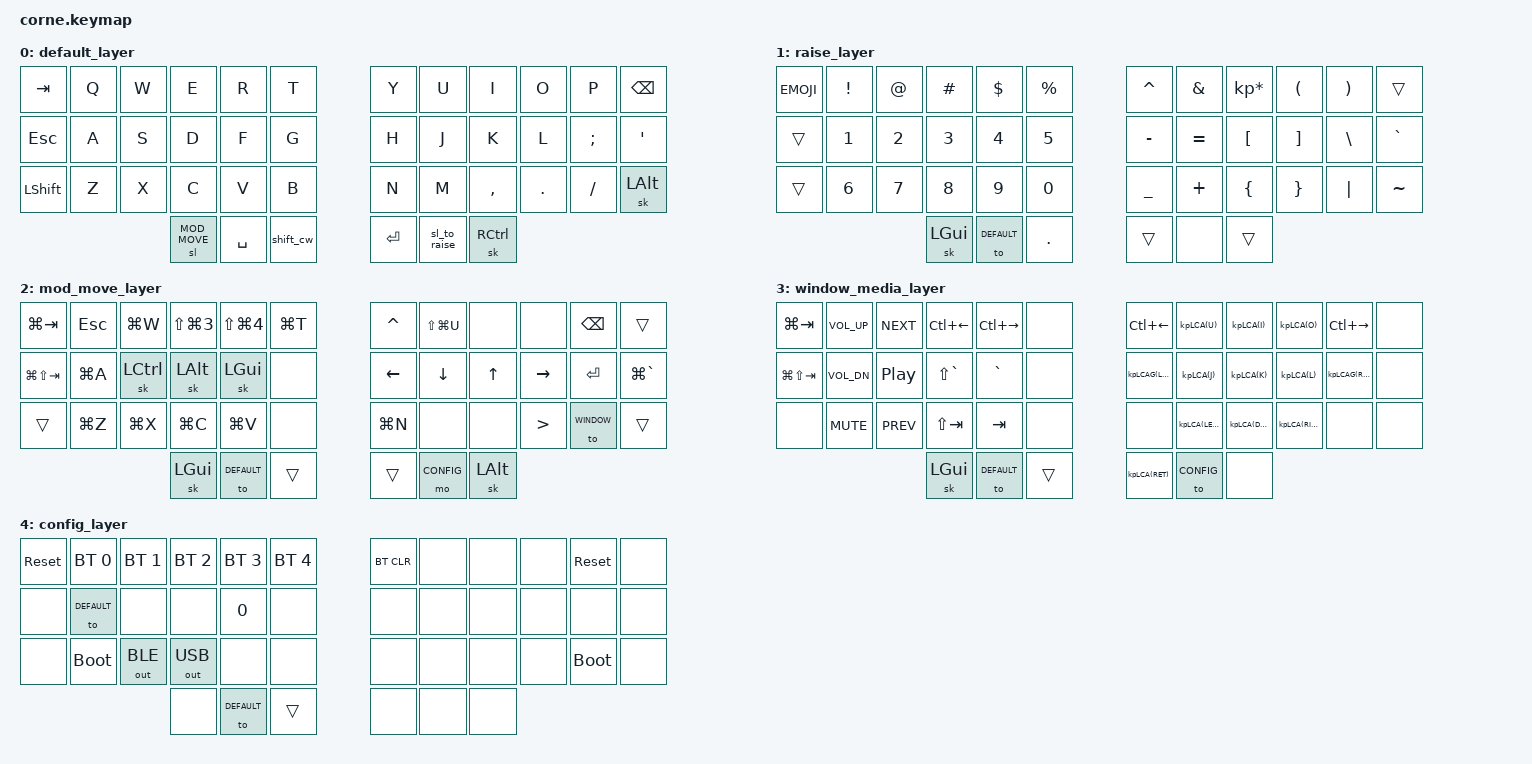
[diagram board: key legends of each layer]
/*
 * Copyright (c) 2020 The ZMK Contributors
 *
 * SPDX-License-Identifier: MIT
 */

#include <behaviors.dtsi>
#include <dt-bindings/zmk/keys.h>
#include <dt-bindings/zmk/bt.h>
#include <dt-bindings/zmk/outputs.h>


#define DEFAULT   0
#define RAISE     1
#define MOD_MOVE  2
#define WINDOW    3
#define CONFIG    4

#define kpLCA(keycode) &kp LC(LA(keycode))
#define kpLCAG(keycode) &kp LC(LA(LG(keycode)))
#define EMOJI LG(LC(SPACE))

&mt {
    tapping-term-ms = <400>;
};

&sk {
    release-after-ms = <10000>;
};

&sl {
    release-after-ms = <10000>;
};

/ {
        behaviors {
           shift_cw: shift_capsword {
                    compatible = "zmk,behavior-tap-dance";
                    label = "STICKY_SHIFT_DOUBLE_TAP_CAPWORD";
                    #binding-cells = <0>;
                    tapping-term-ms = <200>;
                    bindings = <&sk LSHIFT>, <&caps_word>;
           };
           sl_to_raise: sticky_layer_to_layer_raise {
                    compatible = "zmk,behavior-tap-dance";
                    label = "STICKY_LAYER_DOUBLE_TAP_TO_LAYER_RAISE";
                    #binding-cells = <0>;
                    tapping-term-ms = <400>;
                    bindings = <&sl RAISE>, <&to RAISE>;
           };
           my_gresc: grave_escape {
                    compatible = "zmk,behavior-mod-morph";
                    label = "GRAVE_ESCAPE";
                    #binding-cells = <0>;
                    bindings = <&kp ESC>, <&kp GRAVE>;
                    mods = <(MOD_LGUI|MOD_LSFT|MOD_RGUI|MOD_RSFT)>;
                    keep-mods = <(MOD_LGUI|MOD_RGUI)>;
          };
          hm: homerow_mods {
                    compatible = "zmk,behavior-hold-tap";
                    label = "HOMEROW_MODS";
                    #binding-cells = <2>;
                    tapping-term-ms = <300>;
                    quick-tap-ms = <0>;
                    flavor = "tap-unless-interrupted";
                    bindings = <&kp>, <&kp>;
          };
        };

        macros {
          cmd_grave: cmd_grave {
              label = "CMD_GRAVE";
              compatible = "zmk,behavior-macro";
              #binding-cells = <0>;
              bindings
                = <&macro_press &kp LGUI>
                , <&macro_tap &kp GRAVE>
                , <&macro_release &kp LGUI>
                ;
          };
        };

        keymap {
                compatible = "zmk,keymap";

                default_layer {
                        bindings = <
     &kp TAB    &kp Q &kp W &kp E &kp R &kp T   &kp Y &kp U &kp I      &kp O    &kp P    &kp BSPC
     &kp ESC    &kp A &kp S &kp D &kp F &kp G   &kp H &kp J &kp K      &kp L    &kp SEMI &kp SQT
     &kp LSHIFT &kp Z &kp X &kp C &kp V &kp B   &kp N &kp M &kp COMMA  &kp DOT  &kp FSLH &sk LALT
             &sl MOD_MOVE &kp SPACE &shift_cw   &kp RET &sl_to_raise &sk RCTRL
                        >;
                };

                raise_layer {
// -----------------------------------------------------------------------------------------
// |  TAB |  !  |  @  |  #  |  $  |  %  |   |  ^  |  &  |  *  |  (  |  )  | BKSP |
// | CTRL |  1  |  2  |  3  |  4  |  5  |   |  -  |  =  |  [  |  ]  |  \  |  `   |
// | SHFT |  6  |  7  |  8  |  9  |  0  |   |  _  |  +  |  {  |  }  | "|" |  ~   |
//                    |  MM | DEF | SPC |   | ENT | RSE | CTL |
                        bindings = <
   &kp EMOJI   &kp EXCL &kp AT &kp HASH &kp DLLR &kp PRCNT   &kp CARET &kp AMPS  &kp KP_MULTIPLY &kp LPAR &kp RPAR &trans
   &trans      &kp N1   &kp N2 &kp N3   &kp N4   &kp N5      &kp MINUS &kp EQUAL &kp LBKT        &kp RBKT &kp BSLH &kp GRAVE
   &trans      &kp N6   &kp N7 &kp N8   &kp N9   &kp N0      &kp UNDER &kp PLUS  &kp LBRC        &kp RBRC &kp PIPE &kp TILDE
                          &sk LGUI &to DEFAULT   &kp DOT     &trans   &none   &trans
                        >;
                };

                mod_move_layer {
                        bindings = <
&kp LG(TAB)     &kp ESC   &kp LG(W)  &kp LS(LG(N3)) &kp LS(LG(N4)) &kp LG(T)      &kp CARET &kp LS(LG(U)) &none  &none     &kp BSPC   &trans
&kp LG(LS(TAB)) &kp LG(A) &sk LCTRL  &sk LALT       &sk LGUI       &none          &kp LEFT  &kp DOWN      &kp UP &kp RIGHT &kp RET    &kp LG(GRAVE)
&trans          &kp LG(Z) &kp LG(X)  &kp LG(C)      &kp LG(V)      &none          &kp LG(N) &none         &none  &kp GT    &to WINDOW &trans
                    &sk LGUI &to DEFAULT &trans       &trans  &mo CONFIG &sk LALT
                        >;
                };

                window_media_layer {
                        bindings = <
&kp LG(TAB)     &kp C_VOL_UP &kp C_NEXT       &kp LC(LEFT)  &kp LC(RIGHT) &none      &kp LC(LEFT) kpLCA(U)    kpLCA(I)    kpLCA(O)     &kp LC(RIGHT) &none
&kp LG(LS(TAB)) &kp C_VOL_DN &kp C_PLAY_PAUSE &kp LS(GRAVE) &kp GRAVE     &none      kpLCAG(LEFT) kpLCA(J)    kpLCA(K)    kpLCA(L)     kpLCAG(RIGHT) &none
&none           &kp C_MUTE   &kp C_PREV       &kp LS(TAB)   &kp TAB       &none      &none        kpLCA(LEFT) kpLCA(DOWN) kpLCA(RIGHT) &none         &none
                       &sk LGUI   &to DEFAULT  &trans    kpLCA(RET) &to CONFIG  &none
                        >;
                };


                config_layer {
// -----------------------------------------------------------------------------------------
// |      | BT1 | BT2 | BT3 | BT4 | BT5 |   | BT_CLR |     |     |     |     |      |
// |  TAB |  1  |  2  |  3  |  4  |  5  |   |  6     |  7  |  8  |  9  |  0  | BKSP |
// | SHFT |     |     |     |     |     |   |        |     |     |     |     |      |
//                    | GUI |     | SPC |   | ENT    |     | ALT |
                        bindings = <
&sys_reset  &bt BT_SEL 0 &bt BT_SEL 1 &bt BT_SEL 2  &bt BT_SEL 3 &bt BT_SEL 4   &bt BT_CLR &none   &none   &none  &sys_reset  &none
&none       &to DEFAULT  &none        &none         &kp N0       &none          &none      &none   &none   &none  &none       &none
&none       &bootloader  &out OUT_BLE &out OUT_USB  &none        &none          &none      &none   &none   &none  &bootloader &none
                                         &none     &to DEFAULT  &trans     &none  &none   &none
                        >;
                };

// &none  &none  &none  &none  &none  &none          &none  &none  &none  &none  &none  &none
// &none  &none  &none  &none  &none  &none          &none  &none  &none  &none  &none  &none
// &none  &none  &none  &none  &none  &none          &none  &none  &none  &none  &none  &none
//               &none   &to DEFAULT  &none          &none  &none   &none
        };
};
